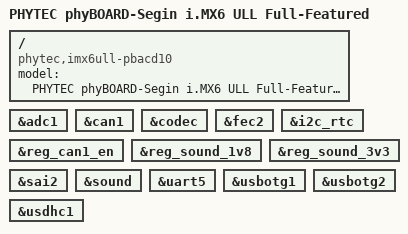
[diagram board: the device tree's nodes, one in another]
// SPDX-License-Identifier: (GPL-2.0+ OR MIT)
/*
 * Copyright (C) 2018 PHYTEC Messtechnik GmbH
 * Author: Stefan Riedmueller <s.riedmueller@phytec.de>
 */

/dts-v1/;
#include <dt-bindings/input/input.h>
#include "imx6ull.dtsi"
#include "imx6ul-phytec-phycore-som.dtsi"
#include "imx6ull-phytec-segin.dtsi"
#include "imx6ul-phytec-segin-peb-av-02.dtsi"
#include "imx6ul-phytec-segin-peb-eval-01.dtsi"
#include "imx6ul-phytec-peb-wlbt-01.dtsi"

/ {

	model = "PHYTEC phyBOARD-Segin i.MX6 ULL Full-Featured";
	compatible = "phytec,imx6ull-pbacd10", "phytec,imx6ull-pcl063",
		     "fsl,imx6ull";
};

&adc1 {
	status = "okay";
};

&can1 {
	status = "okay";
};

&codec {
	status = "okay";
};

&fec2 {
	status = "okay";
};

&i2c_rtc {
	status = "okay";
};

&reg_can1_en {
	status = "okay";
};

&reg_sound_1v8 {
	status = "okay";
};

&reg_sound_3v3 {
	status = "okay";
};

&sai2 {
	status = "okay";
};

&sound {
	status = "okay";
};

&uart5 {
	status = "okay";
};

&usbotg1 {
	status = "okay";
};

&usbotg2 {
	status = "okay";
};

&usdhc1 {
	status = "okay";
};
